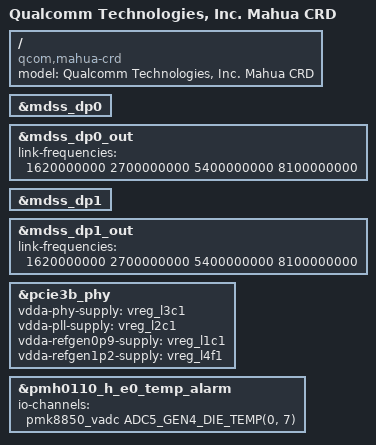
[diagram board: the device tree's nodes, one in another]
// SPDX-License-Identifier: BSD-3-Clause
/*
 * Copyright (c) Qualcomm Technologies, Inc. and/or its subsidiaries.
 */

/dts-v1/;

#include "mahua.dtsi"
#include "glymur-crd.dtsi"

/ {
	model = "Qualcomm Technologies, Inc. Mahua CRD";
	compatible = "qcom,mahua-crd", "qcom,mahua";
};

&mdss_dp0 {
	status = "okay";
};

&mdss_dp0_out {
	link-frequencies = /bits/ 64 <1620000000 2700000000 5400000000 8100000000>;
};

&mdss_dp1 {
	status = "okay";
};

&mdss_dp1_out {
	link-frequencies = /bits/ 64 <1620000000 2700000000 5400000000 8100000000>;
};

&pcie3b_phy {
	vdda-phy-supply = <&vreg_l3c1>;
	vdda-pll-supply = <&vreg_l2c1>;

	vdda-refgen0p9-supply = <&vreg_l1c1>;
	vdda-refgen1p2-supply = <&vreg_l4f1>;
};

&pmh0110_h_e0_temp_alarm {
	io-channels = <&pmk8850_vadc ADC5_GEN4_DIE_TEMP(0, 7)>;
	io-channel-names = "thermal";
};
